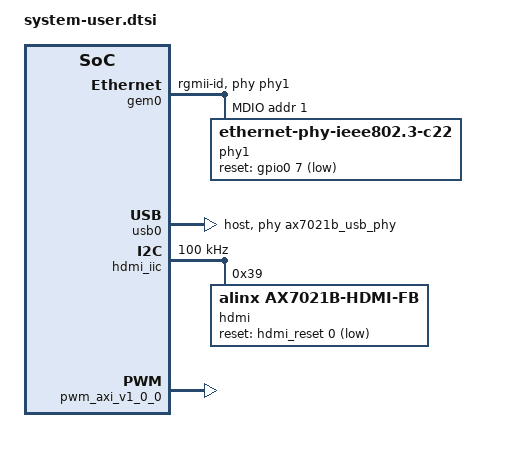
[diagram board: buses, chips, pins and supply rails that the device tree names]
/include/ "system-conf.dtsi"
/ {
	ax7021b_usb_phy: phy@e0002000 {
		compatible = "ulpi-phy";
		#phy-cells = <0>;
		reg = <0xe0002000 0x1000>;
		view-port = <0x0170>;
		drv-vbus;
	};
	chosen {
		bootargs = "console=ttyPS0,115200 earlycon root=/dev/mmcblk0p2 rootfstype=ext4 rootwait rw net.ifnames=0 cma=32M uio_pdrv_genirq.of_id=generic-uio";
	};
};
&gem0 {
	phy-handle = <&phy1>;
	phy-mode = "rgmii-id";
	mdio {
		#address-cells = <1>;
		#size-cells = <0>;
		phy1: ethernet-phy@1 {
			compatible = "ethernet-phy-ieee802.3-c22";
			reg = <1>;
			reset-gpios = <&gpio0 7 1>;
			reset-assert-us = <10000>;
			reset-deassert-us = <100000>;
		};
	};
};
&usb0 {
	status = "okay";
	dr_mode = "host";
	phy_type = "ulpi";
	usb-phy = <&ax7021b_usb_phy>;
};
&hdmi_iic {
	status = "okay";
	clock-frequency = <100000>;
	hdmi@39 {
		compatible = "alinx,ax7021b-hdmi-fb";
		reg = <0x39>;
		dmas = <&display_vdma 0>;
		dma-names = "display";
		clocks = <&clkc 15>;
		clock-names = "display";
		reset-gpios = <&hdmi_reset 0 1>;
	};
};
&pwm_axi_v1_0_0 {
	compatible = "generic-uio";
	linux,uio-name = "ax7021b-pwm";
	status = "okay";
};
